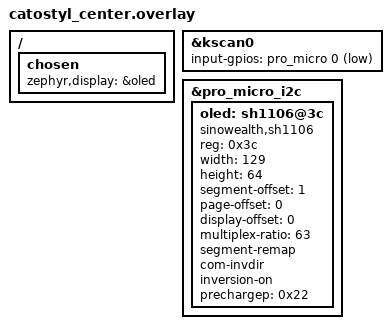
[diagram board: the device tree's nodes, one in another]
#include "catostyl.dtsi"

/ {
    chosen {
        zephyr,display = &oled;
    };
};

&kscan0 {
    input-gpios = <&pro_micro 0 (GPIO_PULL_UP | GPIO_ACTIVE_LOW)>;
};

&pro_micro_i2c {
    status = "okay";

    oled: sh1106@3c {
        compatible = "sinowealth,sh1106";
        reg = <0x3c>;
        width = <129>;
        height = <64>;
        segment-offset = <1>;
        page-offset = <0>;
        display-offset = <0>;
        multiplex-ratio = <63>;
        segment-remap;
        com-invdir;
        inversion-on;
        prechargep = <0x22>;
        };
}; 
